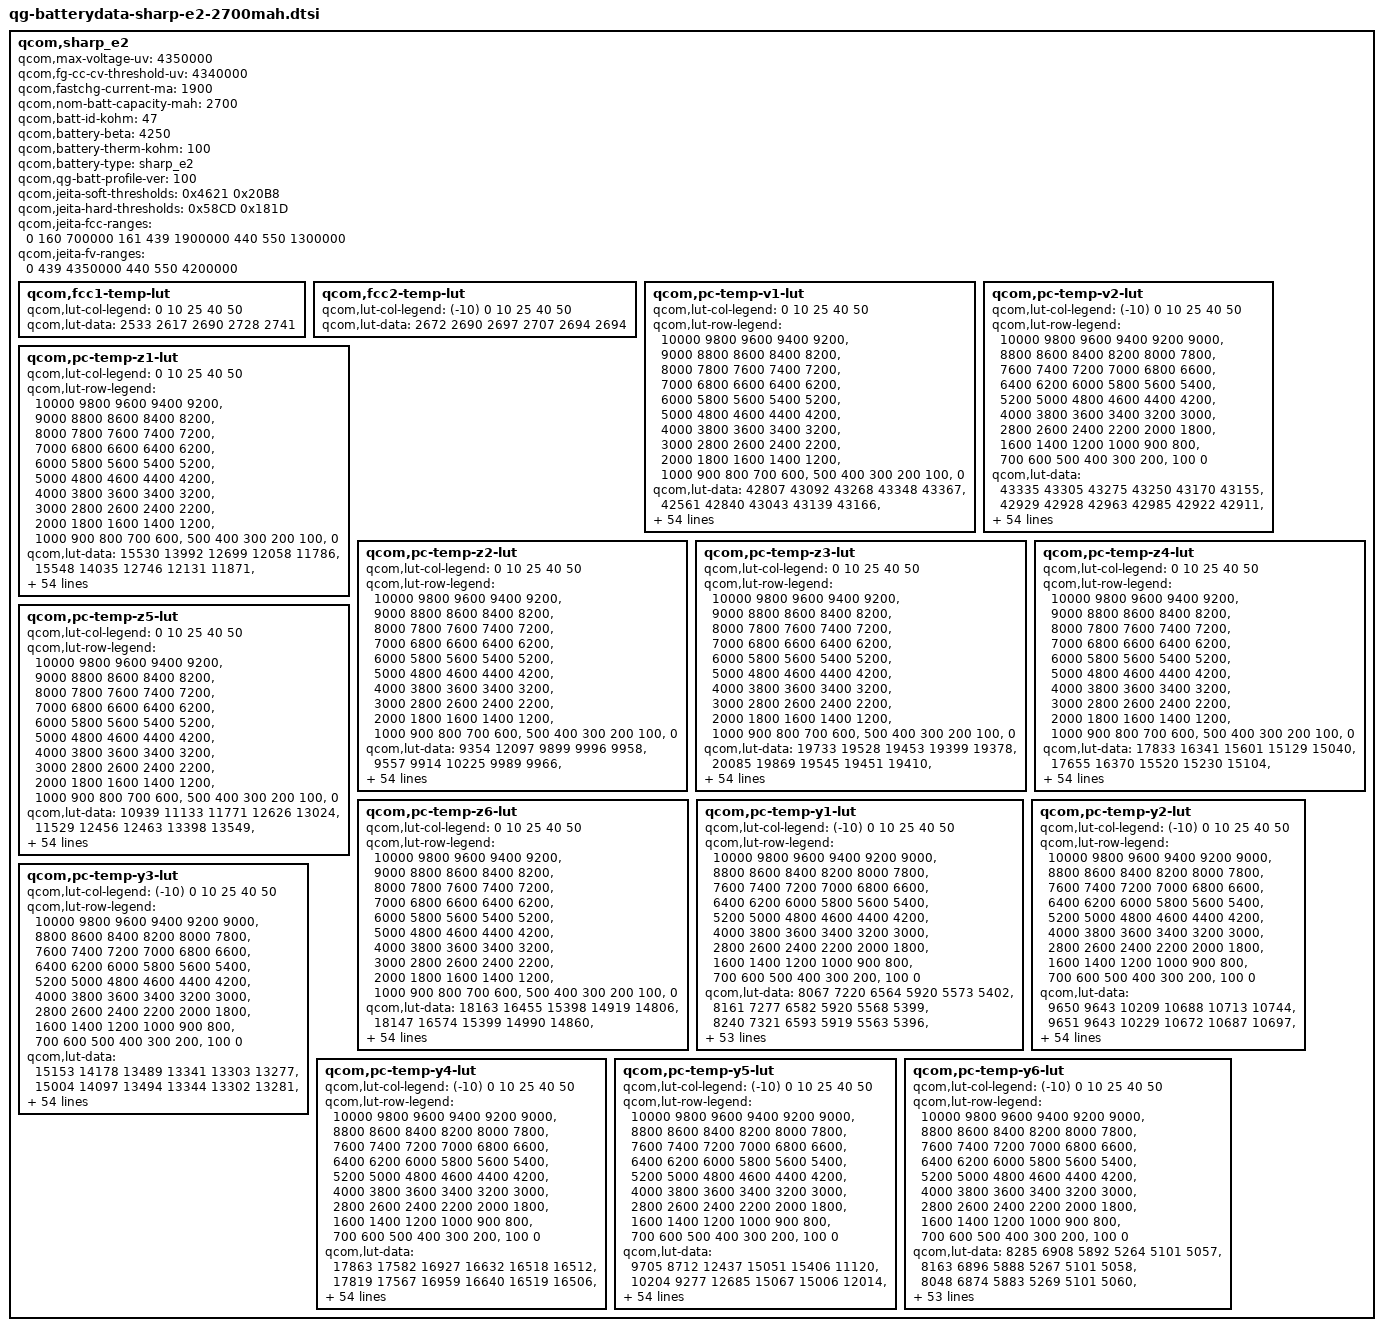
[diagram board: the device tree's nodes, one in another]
/* Copyright (c) 2018, The Linux Foundation. All rights reserved.
 *
 * This program is free software; you can redistribute it and/or modify
 * it under the terms of the GNU General Public License version 2 and
 * only version 2 as published by the Free Software Foundation.
 *
 * This program is distributed in the hope that it will be useful,
 * but WITHOUT ANY WARRANTY; without even the implied warranty of
 * MERCHANTABILITY or FITNESS FOR A PARTICULAR PURPOSE.  See the
 * GNU General Public License for more details.
 */

qcom,sharp_e2 {
	/* sharp_e2 */
	qcom,max-voltage-uv = <4350000>;
	qcom,fg-cc-cv-threshold-uv = <4340000>;
	qcom,fastchg-current-ma = <1900>;
	qcom,nom-batt-capacity-mah = <2700>;
	qcom,batt-id-kohm = <47>;
	qcom,battery-beta = <4250>;
	qcom,battery-therm-kohm = <100>;
	qcom,battery-type = "sharp_e2";
	qcom,qg-batt-profile-ver = <100>;

	qcom,jeita-soft-thresholds = <0x4621 0x20B8>;
	qcom,jeita-hard-thresholds = <0x58CD 0x181D>;

	qcom,jeita-fcc-ranges = <0 160 700000 161 439 1900000 440 550 1300000>;
	qcom,jeita-fv-ranges = <0 439 4350000 440 550 4200000>;

	qcom,fcc1-temp-lut {
		qcom,lut-col-legend = <0 10 25 40 50>;
		qcom,lut-data = <2533 2617 2690 2728 2741>;
	};

	qcom,fcc2-temp-lut {
		qcom,lut-col-legend = <(-10) 0 10 25 40 50>;
		qcom,lut-data = <2672 2690 2697 2707 2694 2694>;
	};

	qcom,pc-temp-v1-lut {
		qcom,lut-col-legend = <0 10 25 40 50>;
		qcom,lut-row-legend = <10000 9800 9600 9400 9200>,
			<9000 8800 8600 8400 8200>,
			<8000 7800 7600 7400 7200>,
			<7000 6800 6600 6400 6200>,
			<6000 5800 5600 5400 5200>,
			<5000 4800 4600 4400 4200>,
			<4000 3800 3600 3400 3200>,
			<3000 2800 2600 2400 2200>,
			<2000 1800 1600 1400 1200>,
			<1000 900 800 700 600>,
			<500 400 300 200 100>,
			<0>;
		qcom,lut-data = <42807 43092 43268 43348 43367>,
			<42561 42840 43043 43139 43166>,
			<42329 42609 42816 42914 42945>,
			<42112 42390 42590 42687 42720>,
			<41905 42175 42362 42464 42499>,
			<41702 41962 42138 42242 42279>,
			<41501 41753 41919 42021 42059>,
			<41305 41547 41704 41803 41840>,
			<41123 41347 41494 41588 41622>,
			<40954 41155 41286 41375 41409>,
			<40772 40981 41087 41167 41199>,
			<40546 40805 40901 40965 40995>,
			<40302 40602 40720 40769 40796>,
			<40104 40373 40531 40580 40603>,
			<39950 40173 40336 40394 40416>,
			<39814 40019 40155 40215 40235>,
			<39685 39882 39998 40046 40064>,
			<39564 39748 39851 39888 39905>,
			<39449 39620 39700 39727 39744>,
			<39338 39492 39551 39566 39578>,
			<39232 39361 39382 39395 39405>,
			<39132 39227 39146 39185 39211>,
			<39035 39087 38903 38938 38985>,
			<38946 38931 38744 38765 38806>,
			<38862 38782 38626 38667 38694>,
			<38783 38656 38541 38588 38603>,
			<38708 38544 38481 38505 38510>,
			<38640 38461 38433 38426 38418>,
			<38576 38401 38382 38349 38333>,
			<38516 38354 38331 38274 38253>,
			<38461 38315 38282 38205 38181>,
			<38408 38282 38236 38149 38120>,
			<38359 38251 38191 38099 38068>,
			<38312 38223 38146 38048 38013>,
			<38266 38197 38104 37997 37957>,
			<38220 38164 38060 37945 37900>,
			<38174 38128 38016 37895 37839>,
			<38120 38082 37967 37843 37775>,
			<38058 38012 37898 37776 37700>,
			<37983 37915 37797 37684 37608>,
			<37886 37806 37684 37576 37503>,
			<37761 37678 37562 37455 37385>,
			<37621 37536 37426 37319 37254>,
			<37467 37372 37265 37166 37102>,
			<37323 37249 37140 37041 36978>,
			<37229 37176 37061 36968 36905>,
			<37193 37140 37042 36945 36887>,
			<37164 37113 37021 36932 36871>,
			<37130 37085 37001 36910 36848>,
			<37052 37022 36936 36837 36765>,
			<36810 36762 36661 36553 36467>,
			<36368 36323 36231 36120 36033>,
			<35809 35762 35672 35559 35470>,
			<35057 35006 34916 34798 34708>,
			<33873 33833 33755 33637 33545>,
			<30000 30000 30000 30000 30000>;
	};

	qcom,pc-temp-v2-lut {
		qcom,lut-col-legend = <(-10) 0 10 25 40 50>;
		qcom,lut-row-legend = <10000 9800 9600 9400 9200 9000>,
			<8800 8600 8400 8200 8000 7800>,
			<7600 7400 7200 7000 6800 6600>,
			<6400 6200 6000 5800 5600 5400>,
			<5200 5000 4800 4600 4400 4200>,
			<4000 3800 3600 3400 3200 3000>,
			<2800 2600 2400 2200 2000 1800>,
			<1600 1400 1200 1000 900 800>,
			<700 600 500 400 300 200>,
			<100 0>;
		qcom,lut-data = <43335 43305 43275 43250 43170 43155>,
			<42929 42928 42963 42985 42922 42911>,
			<42563 42588 42674 42731 42683 42676>,
			<42244 42293 42411 42490 42451 42448>,
			<41965 42037 42171 42262 42229 42228>,
			<41710 41791 41942 42040 42010 42011>,
			<41461 41520 41718 41819 41793 41795>,
			<41235 41266 41501 41602 41579 41580>,
			<41073 41108 41285 41389 41368 41370>,
			<40970 41018 41069 41179 41160 41163>,
			<40843 40902 40866 40976 40958 40960>,
			<40526 40612 40691 40785 40762 40762>,
			<40074 40217 40523 40599 40572 40568>,
			<39777 39953 40331 40408 40386 40383>,
			<39594 39776 40110 40209 40205 40204>,
			<39432 39607 39891 40024 40030 40031>,
			<39255 39411 39688 39867 39867 39868>,
			<39081 39212 39491 39717 39709 39708>,
			<38916 39029 39293 39537 39534 39535>,
			<38757 38858 39092 39328 39341 39349>,
			<38614 38700 38907 39123 39148 39161>,
			<38496 38548 38746 38927 38953 38966>,
			<38392 38411 38600 38746 38766 38777>,
			<38306 38306 38470 38602 38622 38631>,
			<38234 38225 38351 38484 38509 38517>,
			<38169 38157 38244 38380 38409 38415>,
			<38108 38099 38147 38287 38315 38319>,
			<38050 38047 38061 38203 38228 38230>,
			<37994 37999 37996 38122 38149 38150>,
			<37939 37955 37945 38045 38077 38076>,
			<37885 37911 37899 37975 38009 38008>,
			<37832 37867 37853 37908 37945 37945>,
			<37780 37823 37809 37847 37884 37885>,
			<37725 37777 37765 37790 37817 37814>,
			<37667 37730 37723 37740 37742 37728>,
			<37608 37679 37677 37687 37663 37636>,
			<37546 37621 37624 37627 37578 37539>,
			<37484 37557 37563 37564 37489 37438>,
			<37419 37484 37493 37495 37407 37350>,
			<37351 37401 37413 37421 37335 37276>,
			<37282 37310 37323 37335 37257 37196>,
			<37209 37209 37217 37229 37156 37095>,
			<37134 37104 37100 37109 37039 36980>,
			<37052 37007 36977 36972 36903 36845>,
			<36957 36917 36865 36869 36817 36769>,
			<36840 36835 36785 36820 36784 36739>,
			<36778 36793 36750 36798 36769 36724>,
			<36699 36742 36704 36774 36749 36704>,
			<36588 36673 36636 36728 36708 36665>,
			<36435 36561 36543 36617 36578 36516>,
			<36199 36325 36305 36297 36233 36162>,
			<35833 35913 35862 35805 35750 35677>,
			<35289 35316 35256 35175 35126 35049>,
			<34478 34455 34415 34312 34294 34216>,
			<33103 33147 33094 33108 33164 33127>,
			<30084 30046 30023 30020 30017 30016>;
	};

	qcom,pc-temp-z1-lut {
		qcom,lut-col-legend = <0 10 25 40 50>;
		qcom,lut-row-legend = <10000 9800 9600 9400 9200>,
			<9000 8800 8600 8400 8200>,
			<8000 7800 7600 7400 7200>,
			<7000 6800 6600 6400 6200>,
			<6000 5800 5600 5400 5200>,
			<5000 4800 4600 4400 4200>,
			<4000 3800 3600 3400 3200>,
			<3000 2800 2600 2400 2200>,
			<2000 1800 1600 1400 1200>,
			<1000 900 800 700 600>,
			<500 400 300 200 100>,
			<0>;
		qcom,lut-data = <15530 13992 12699 12058 11786>,
			<15548 14035 12746 12131 11871>,
			<15563 14057 12776 12148 11882>,
			<15574 14072 12781 12154 11887>,
			<15588 14078 12780 12148 11885>,
			<15598 14080 12777 12136 11879>,
			<15640 14082 12766 12127 11873>,
			<15694 14089 12752 12120 11869>,
			<15698 14104 12744 12113 11865>,
			<15674 14111 12737 12109 11863>,
			<15648 14106 12734 12105 11860>,
			<15604 14096 12733 12103 11859>,
			<15525 14080 12733 12100 11857>,
			<15481 14056 12731 12099 11856>,
			<15472 14043 12726 12098 11856>,
			<15464 14044 12723 12097 11855>,
			<15454 14049 12728 12098 11855>,
			<15437 14052 12734 12099 11856>,
			<15418 14054 12736 12100 11858>,
			<15403 14058 12738 12103 11858>,
			<15388 14085 12740 12105 11859>,
			<15372 14125 12750 12107 11860>,
			<15352 14136 12761 12109 11862>,
			<15336 14116 12762 12111 11865>,
			<15329 14099 12759 12114 11868>,
			<15327 14109 12757 12117 11873>,
			<15322 14131 12760 12121 11877>,
			<15294 14142 12765 12127 11883>,
			<15255 14142 12772 12133 11889>,
			<15238 14141 12781 12140 11894>,
			<15234 14141 12786 12146 11900>,
			<15232 14139 12788 12151 11905>,
			<15230 14141 12789 12155 11911>,
			<15233 14155 12794 12160 11916>,
			<15238 14172 12809 12166 11921>,
			<15252 14179 12818 12172 11926>,
			<15276 14183 12819 12177 11931>,
			<15292 14187 12820 12182 11936>,
			<15344 14190 12822 12188 11941>,
			<15391 14193 12831 12194 11946>,
			<15396 14199 12840 12200 11951>,
			<15400 14214 12847 12205 11956>,
			<15384 14219 12855 12211 11962>,
			<15335 14201 12865 12220 11967>,
			<15336 14178 12867 12230 11974>,
			<15316 14149 12888 12237 11980>,
			<15275 14151 12872 12236 11981>,
			<15285 14152 12868 12242 11984>,
			<15299 14167 12869 12243 11988>,
			<15300 14168 12873 12250 11995>,
			<15286 14170 12893 12268 12008>,
			<15343 14194 12914 12273 12016>,
			<15373 14252 12926 12290 12031>,
			<15374 14248 12972 12319 12051>,
			<15374 14248 12972 12319 12051>,
			<15374 14248 12972 12319 12051>;
	};

	qcom,pc-temp-z2-lut {
		qcom,lut-col-legend = <0 10 25 40 50>;
		qcom,lut-row-legend = <10000 9800 9600 9400 9200>,
			<9000 8800 8600 8400 8200>,
			<8000 7800 7600 7400 7200>,
			<7000 6800 6600 6400 6200>,
			<6000 5800 5600 5400 5200>,
			<5000 4800 4600 4400 4200>,
			<4000 3800 3600 3400 3200>,
			<3000 2800 2600 2400 2200>,
			<2000 1800 1600 1400 1200>,
			<1000 900 800 700 600>,
			<500 400 300 200 100>,
			<0>;
		qcom,lut-data = <9354 12097 9899 9996 9958>,
			<9557 9914 10225 9989 9966>,
			<9682 9800 10389 10024 10015>,
			<9702 9779 10350 10042 10046>,
			<9711 9769 10085 10023 10029>,
			<9714 9760 9909 9988 9979>,
			<9715 9754 9879 9972 9957>,
			<9717 9754 9862 9963 9954>,
			<9713 9757 9861 9957 9951>,
			<9698 9759 9865 9956 9933>,
			<9681 9760 9871 9957 9896>,
			<9666 9761 9939 9956 9878>,
			<9651 9755 10042 9955 9860>,
			<9641 9735 10089 9954 9851>,
			<9633 9725 10117 9955 9854>,
			<9627 9731 10129 9956 9858>,
			<9620 9742 10063 9958 9864>,
			<9612 9752 9964 9957 9878>,
			<9607 9762 9951 9959 9891>,
			<9605 9770 9962 9990 9909>,
			<9604 9775 9967 10030 9930>,
			<9603 9779 9963 10033 9929>,
			<9603 9785 9955 10013 9914>,
			<9603 9797 9953 9994 9905>,
			<9604 9810 9951 9955 9917>,
			<9606 9818 9952 9920 9940>,
			<9607 9825 9954 9946 9969>,
			<9583 9830 9955 10031 10012>,
			<9526 9836 9964 10071 10034>,
			<9486 9841 9991 10069 10009>,
			<9430 9846 10009 10058 9966>,
			<9377 9850 10011 10031 9924>,
			<9359 9855 10010 9990 9860>,
			<9348 9861 10009 9978 9838>,
			<9340 9868 10007 10002 9869>,
			<9337 9876 10005 10034 9913>,
			<9336 9885 10010 10058 9947>,
			<9326 9895 10019 10080 9981>,
			<9269 9904 10030 10098 10005>,
			<9205 9914 10049 10115 10026>,
			<9187 9922 10059 10125 10038>,
			<9195 9927 10058 10124 10025>,
			<9216 9936 10057 10122 10005>,
			<9255 9965 10063 10130 10007>,
			<9304 9963 10113 10126 10012>,
			<9305 9820 10169 10075 10010>,
			<9334 9821 10153 10085 10029>,
			<9344 9835 10146 10077 10031>,
			<9336 9961 10200 10093 10050>,
			<9333 10075 10211 10172 10139>,
			<9321 9889 10251 10193 10025>,
			<9285 9781 10197 10141 9958>,
			<9211 9627 10155 10123 9928>,
			<9170 9509 10124 10057 9903>,
			<9170 9509 10124 10057 9903>,
			<9170 9509 10124 10057 9903>;
	};

	qcom,pc-temp-z3-lut {
		qcom,lut-col-legend = <0 10 25 40 50>;
		qcom,lut-row-legend = <10000 9800 9600 9400 9200>,
			<9000 8800 8600 8400 8200>,
			<8000 7800 7600 7400 7200>,
			<7000 6800 6600 6400 6200>,
			<6000 5800 5600 5400 5200>,
			<5000 4800 4600 4400 4200>,
			<4000 3800 3600 3400 3200>,
			<3000 2800 2600 2400 2200>,
			<2000 1800 1600 1400 1200>,
			<1000 900 800 700 600>,
			<500 400 300 200 100>,
			<0>;
		qcom,lut-data = <19733 19528 19453 19399 19378>,
			<20085 19869 19545 19451 19410>,
			<20272 19948 19611 19496 19450>,
			<20246 19989 19645 19522 19475>,
			<20175 19996 19675 19534 19482>,
			<20148 19994 19690 19543 19486>,
			<20157 19991 19692 19543 19486>,
			<20168 19985 19693 19532 19480>,
			<20175 19975 19689 19520 19472>,
			<20182 19960 19669 19511 19463>,
			<20191 19919 19654 19501 19452>,
			<20207 19878 19648 19490 19445>,
			<20228 19889 19645 19478 19437>,
			<20234 19937 19642 19470 19429>,
			<20212 19960 19635 19466 19426>,
			<20177 19930 19626 19463 19423>,
			<20146 19880 19605 19458 19418>,
			<20117 19849 19584 19452 19408>,
			<20085 19824 19581 19450 19402>,
			<20048 19811 19582 19455 19407>,
			<20007 19820 19585 19462 19416>,
			<19965 19843 19597 19465 19417>,
			<19922 19864 19611 19466 19409>,
			<19878 19888 19611 19462 19401>,
			<19835 19904 19602 19444 19389>,
			<19794 19905 19592 19426 19379>,
			<19754 19904 19580 19427 19386>,
			<19714 19901 19570 19436 19419>,
			<19674 19894 19569 19448 19442>,
			<19636 19882 19573 19479 19456>,
			<19600 19871 19579 19505 19467>,
			<19566 19857 19587 19502 19462>,
			<19536 19843 19595 19490 19442>,
			<19508 19828 19596 19480 19428>,
			<19485 19812 19594 19472 19420>,
			<19471 19795 19590 19466 19414>,
			<19462 19776 19584 19460 19413>,
			<19453 19763 19577 19455 19412>,
			<19415 19760 19570 19450 19411>,
			<19368 19758 19564 19443 19409>,
			<19341 19753 19559 19438 19407>,
			<19313 19738 19555 19439 19404>,
			<19294 19720 19551 19440 19401>,
			<19282 19701 19545 19435 19400>,
			<19277 19506 19514 19422 19394>,
			<19277 19265 19495 19403 19382>,
			<19275 19265 19469 19404 19371>,
			<19274 19265 19464 19390 19367>,
			<19274 19264 19430 19388 19363>,
			<19274 19262 19429 19370 19354>,
			<19274 19264 19416 19367 19374>,
			<19277 19265 19396 19370 19382>,
			<19285 19268 19380 19367 19383>,
			<19292 19272 19380 19374 19386>,
			<19292 19272 19380 19374 19386>,
			<19292 19272 19380 19374 19386>;
	};

	qcom,pc-temp-z4-lut {
		qcom,lut-col-legend = <0 10 25 40 50>;
		qcom,lut-row-legend = <10000 9800 9600 9400 9200>,
			<9000 8800 8600 8400 8200>,
			<8000 7800 7600 7400 7200>,
			<7000 6800 6600 6400 6200>,
			<6000 5800 5600 5400 5200>,
			<5000 4800 4600 4400 4200>,
			<4000 3800 3600 3400 3200>,
			<3000 2800 2600 2400 2200>,
			<2000 1800 1600 1400 1200>,
			<1000 900 800 700 600>,
			<500 400 300 200 100>,
			<0>;
		qcom,lut-data = <17833 16341 15601 15129 15040>,
			<17655 16370 15520 15230 15104>,
			<17478 16231 15434 15168 15066>,
			<17302 15955 15337 15093 15010>,
			<17126 15758 15229 15033 14965>,
			<16939 15617 15137 14974 14922>,
			<16726 15502 15063 14926 14886>,
			<16520 15410 14999 14882 14854>,
			<16339 15333 14948 14854 14831>,
			<16168 15274 14906 14839 14819>,
			<16046 15234 14873 14828 14811>,
			<15983 15196 14836 14817 14803>,
			<15937 15138 14803 14807 14793>,
			<15880 15060 14792 14796 14781>,
			<15803 15009 14786 14783 14768>,
			<15731 14989 14781 14769 14755>,
			<15687 14974 14780 14758 14746>,
			<15653 14961 14783 14747 14738>,
			<15637 14951 14782 14743 14735>,
			<15636 14938 14780 14748 14740>,
			<15638 14913 14781 14759 14754>,
			<15642 14881 14868 14812 14794>,
			<15654 14874 14993 14945 14912>,
			<15670 14891 15033 15003 14977>,
			<15683 14913 15050 15000 14973>,
			<15695 14937 15056 14992 14964>,
			<15706 14968 15038 14975 14941>,
			<15718 14979 15003 14939 14882>,
			<15730 14969 14971 14898 14832>,
			<15737 14953 14938 14845 14794>,
			<15750 14936 14905 14799 14764>,
			<15764 14918 14872 14778 14752>,
			<15772 14901 14843 14765 14745>,
			<15775 14885 14824 14762 14743>,
			<15770 14872 14810 14764 14747>,
			<15747 14863 14803 14766 14752>,
			<15715 14855 14800 14769 14757>,
			<15702 14849 14799 14773 14763>,
			<15687 14842 14802 14780 14769>,
			<15667 14834 14816 14792 14778>,
			<15647 14832 14825 14801 14783>,
			<15620 14835 14815 14794 14780>,
			<15581 14836 14801 14783 14775>,
			<15513 14826 14797 14786 14777>,
			<15300 14928 14771 14772 14768>,
			<15275 15120 14732 14740 14734>,
			<15268 15111 14735 14719 14721>,
			<15256 15101 14725 14703 14694>,
			<15247 15089 14743 14682 14670>,
			<15236 15079 14740 14708 14688>,
			<15240 15098 14791 14758 14721>,
			<15289 15125 14826 14763 14720>,
			<15322 15141 14851 14770 14723>,
			<15364 15164 14860 14767 14723>,
			<15364 15164 14860 14767 14723>,
			<15364 15164 14860 14767 14723>;
	};

	qcom,pc-temp-z5-lut {
		qcom,lut-col-legend = <0 10 25 40 50>;
		qcom,lut-row-legend = <10000 9800 9600 9400 9200>,
			<9000 8800 8600 8400 8200>,
			<8000 7800 7600 7400 7200>,
			<7000 6800 6600 6400 6200>,
			<6000 5800 5600 5400 5200>,
			<5000 4800 4600 4400 4200>,
			<4000 3800 3600 3400 3200>,
			<3000 2800 2600 2400 2200>,
			<2000 1800 1600 1400 1200>,
			<1000 900 800 700 600>,
			<500 400 300 200 100>,
			<0>;
		qcom,lut-data = <10939 11133 11771 12626 13024>,
			<11529 12456 12463 13398 13549>,
			<11908 12849 13114 14150 14459>,
			<11995 13074 13652 14714 15162>,
			<12055 13247 14364 15184 15471>,
			<12155 13385 15053 15619 15657>,
			<12392 13516 15642 15993 15907>,
			<12692 13730 16211 16471 16340>,
			<12924 14028 16790 16727 16732>,
			<13117 14142 17387 16785 16827>,
			<13315 13898 17761 16839 16704>,
			<13584 13616 18536 16832 16628>,
			<13859 14117 19513 16793 16620>,
			<13960 15973 20000 16807 16776>,
			<13933 17002 20691 17243 17395>,
			<13861 16598 21000 17968 18214>,
			<13771 15961 20790 18559 18409>,
			<13637 15768 20491 19135 18312>,
			<13479 15752 20833 20008 18257>,
			<13279 15797 22801 22412 20083>,
			<13048 16815 25366 25018 22914>,
			<12844 19475 29759 25498 23014>,
			<12657 22841 33920 24604 20639>,
			<12479 28645 33563 23226 18174>,
			<12320 33306 29455 19749 15964>,
			<12175 34080 25531 16378 14216>,
			<12043 34168 22649 15683 14217>,
			<11918 33819 20457 15399 15208>,
			<11796 32564 19905 15531 16328>,
			<11677 30838 19819 18175 18854>,
			<11555 29336 19978 21363 21297>,
			<11441 27860 21173 22666 21477>,
			<11349 26452 23194 23543 21368>,
			<11267 25067 25134 24537 21362>,
			<11194 23771 27357 25963 22214>,
			<11134 22741 28428 26902 23081>,
			<11075 21707 28360 26557 23080>,
			<10992 21145 28179 25421 22881>,
			<10806 21669 27658 23936 22476>,
			<10638 22742 25985 21301 20776>,
			<10612 22973 24555 19510 18984>,
			<10615 21451 23876 19538 18217>,
			<10632 20490 23384 19621 17691>,
			<10682 20382 22794 18602 17210>,
			<10927 15884 22124 18227 16907>,
			<10906 10966 22565 17558 16877>,
			<10882 10954 18424 18306 16165>,
			<10870 10942 17957 17254 16934>,
			<10872 10916 15987 18546 18825>,
			<10894 10918 15929 15684 16069>,
			<10912 10984 14148 13636 14805>,
			<10884 10915 13012 13337 14714>,
			<10801 10858 12408 12945 14391>,
			<10739 10788 12218 13015 14157>,
			<10739 10788 12218 13015 14157>,
			<10739 10788 12218 13015 14157>;
	};

	qcom,pc-temp-z6-lut {
		qcom,lut-col-legend = <0 10 25 40 50>;
		qcom,lut-row-legend = <10000 9800 9600 9400 9200>,
			<9000 8800 8600 8400 8200>,
			<8000 7800 7600 7400 7200>,
			<7000 6800 6600 6400 6200>,
			<6000 5800 5600 5400 5200>,
			<5000 4800 4600 4400 4200>,
			<4000 3800 3600 3400 3200>,
			<3000 2800 2600 2400 2200>,
			<2000 1800 1600 1400 1200>,
			<1000 900 800 700 600>,
			<500 400 300 200 100>,
			<0>;
		qcom,lut-data = <18163 16455 15398 14919 14806>,
			<18147 16574 15399 14990 14860>,
			<18103 16509 15390 14986 14861>,
			<18006 16366 15366 14979 14861>,
			<17830 16251 15316 14962 14854>,
			<17666 16157 15270 14935 14834>,
			<17529 16076 15232 14910 14815>,
			<17407 16012 15194 14884 14797>,
			<17305 15959 15159 14863 14782>,
			<17213 15906 15126 14850 14771>,
			<17141 15850 15099 14839 14761>,
			<17096 15800 15079 14828 14752>,
			<17061 15767 15063 14816 14743>,
			<17018 15743 15052 14806 14734>,
			<16957 15719 15045 14798 14726>,
			<16894 15691 15038 14790 14719>,
			<16850 15666 15026 14782 14711>,
			<16815 15648 15016 14774 14702>,
			<16786 15630 15015 14771 14698>,
			<16758 15620 15016 14775 14702>,
			<16730 15620 15018 14784 14712>,
			<16704 15625 15064 14810 14732>,
			<16679 15635 15126 14868 14778>,
			<16654 15655 15142 14892 14803>,
			<16630 15678 15147 14884 14798>,
			<16607 15696 15148 14871 14789>,
			<16583 15713 15137 14862 14782>,
			<16555 15718 15118 14854 14775>,
			<16526 15712 15105 14847 14769>,
			<16505 15702 15095 14841 14762>,
			<16488 15692 15087 14835 14755>,
			<16474 15679 15079 14826 14746>,
			<16459 15668 15073 14815 14733>,
			<16443 15658 15068 14809 14727>,
			<16430 15650 15064 14807 14725>,
			<16424 15643 15061 14805 14724>,
			<16420 15637 15059 14805 14725>,
			<16421 15634 15058 14805 14727>,
			<16430 15635 15059 14806 14730>,
			<16436 15636 15067 14809 14734>,
			<16432 15637 15071 14812 14736>,
			<16427 15636 15069 14811 14734>,
			<16413 15634 15066 14808 14731>,
			<16374 15626 15066 14808 14733>,
			<16274 15573 15048 14799 14726>,
			<16267 15548 15027 14777 14706>,
			<16260 15547 15016 14769 14696>,
			<16255 15544 15012 14756 14682>,
			<16256 15542 15005 14747 14670>,
			<16261 15546 15007 14751 14675>,
			<16275 15568 15028 14774 14702>,
			<16309 15594 15042 14782 14709>,
			<16344 15622 15054 14787 14715>,
			<16396 15662 15072 14797 14722>,
			<16396 15662 15072 14797 14722>,
			<16396 15662 15072 14797 14722>;
	};

	qcom,pc-temp-y1-lut {
		qcom,lut-col-legend = <(-10) 0 10 25 40 50>;
		qcom,lut-row-legend = <10000 9800 9600 9400 9200 9000>,
			<8800 8600 8400 8200 8000 7800>,
			<7600 7400 7200 7000 6800 6600>,
			<6400 6200 6000 5800 5600 5400>,
			<5200 5000 4800 4600 4400 4200>,
			<4000 3800 3600 3400 3200 3000>,
			<2800 2600 2400 2200 2000 1800>,
			<1600 1400 1200 1000 900 800>,
			<700 600 500 400 300 200>,
			<100 0>;
		qcom,lut-data = <8067 7220 6564 5920 5573 5402>,
			<8161 7277 6582 5920 5568 5399>,
			<8240 7321 6593 5919 5563 5396>,
			<8300 7353 6598 5917 5558 5393>,
			<8338 7372 6599 5914 5553 5389>,
			<8352 7379 6597 5910 5548 5385>,
			<8335 7366 6590 5905 5544 5380>,
			<8301 7344 6580 5899 5540 5374>,
			<8278 7339 6578 5898 5536 5371>,
			<8273 7336 6591 5901 5532 5369>,
			<8279 7335 6600 5903 5529 5367>,
			<8307 7334 6591 5900 5525 5364>,
			<8347 7332 6578 5894 5521 5362>,
			<8365 7334 6579 5892 5519 5360>,
			<8346 7338 6592 5887 5517 5357>,
			<8332 7345 6599 5884 5516 5356>,
			<8316 7373 6591 5889 5515 5356>,
			<8271 7413 6578 5898 5514 5357>,
			<8249 7414 6575 5900 5513 5357>,
			<8242 7366 6576 5899 5513 5358>,
			<8237 7330 6577 5898 5512 5358>,
			<8234 7342 6583 5900 5513 5359>,
			<8232 7362 6593 5903 5515 5359>,
			<8230 7366 6595 5904 5516 5361>,
			<8227 7365 6594 5904 5518 5363>,
			<8223 7362 6593 5905 5520 5366>,
			<8225 7343 6596 5909 5524 5369>,
			<8237 7310 6600 5912 5529 5372>,
			<8247 7302 6600 5912 5533 5375>,
			<8263 7305 6603 5909 5538 5378>,
			<8275 7307 6606 5908 5542 5382>,
			<8266 7306 6607 5911 5546 5387>,
			<8244 7303 6608 5916 5550 5391>,
			<8234 7307 6608 5918 5554 5395>,
			<8241 7338 6600 5919 5558 5398>,
			<8255 7360 6595 5919 5561 5400>,
			<8259 7349 6594 5921 5562 5404>,
			<8237 7325 6594 5923 5563 5408>,
			<8214 7314 6593 5925 5565 5411>,
			<8219 7331 6588 5928 5573 5413>,
			<8241 7350 6586 5933 5580 5415>,
			<8256 7342 6592 5944 5581 5419>,
			<8248 7324 6600 5950 5582 5424>,
			<8225 7360 6603 5949 5586 5429>,
			<8222 7355 6604 5951 5594 5436>,
			<8215 7327 6629 5965 5602 5439>,
			<8215 7341 6605 5957 5612 5440>,
			<8215 7333 6648 5955 5609 5441>,
			<8276 7369 6615 5966 5605 5441>,
			<8358 7345 6601 5964 5604 5443>,
			<8375 7347 6625 5968 5611 5449>,
			<8394 7387 6623 5983 5622 5456>,
			<8451 7484 6658 6011 5639 5467>,
			<8572 7552 6690 6027 5663 5481>,
			<8572 7552 6690 6027 5663 5481>,
			<8572 7552 6690 6027 5663 5481>;
	};

	qcom,pc-temp-y2-lut {
		qcom,lut-col-legend = <(-10) 0 10 25 40 50>;
		qcom,lut-row-legend = <10000 9800 9600 9400 9200 9000>,
			<8800 8600 8400 8200 8000 7800>,
			<7600 7400 7200 7000 6800 6600>,
			<6400 6200 6000 5800 5600 5400>,
			<5200 5000 4800 4600 4400 4200>,
			<4000 3800 3600 3400 3200 3000>,
			<2800 2600 2400 2200 2000 1800>,
			<1600 1400 1200 1000 900 800>,
			<700 600 500 400 300 200>,
			<100 0>;
		qcom,lut-data = <9650 9643 10209 10688 10713 10744>,
			<9651 9643 10229 10672 10687 10697>,
			<9651 9643 10260 10656 10662 10650>,
			<9652 9722 10291 10641 10638 10608>,
			<9652 9806 10316 10626 10617 10577>,
			<9653 9836 10326 10612 10600 10562>,
			<9653 9788 10323 10596 10585 10566>,
			<9653 9708 10319 10582 10573 10575>,
			<9653 9739 10325 10573 10574 10569>,
			<9654 10011 10367 10567 10589 10540>,
			<9655 10198 10411 10565 10606 10521>,
			<9655 10034 10440 10569 10621 10528>,
			<9654 9757 10465 10578 10638 10544>,
			<9654 9688 10486 10591 10656 10563>,
			<9654 9682 10504 10615 10678 10594>,
			<9654 9678 10517 10642 10703 10629>,
			<9654 9674 10524 10680 10735 10664>,
			<9654 9671 10530 10714 10768 10698>,
			<9654 9669 10538 10716 10786 10728>,
			<9654 9667 10546 10706 10799 10770>,
			<9654 9665 10555 10700 10804 10795>,
			<9654 9665 10570 10708 10776 10753>,
			<9654 9665 10586 10724 10731 10680>,
			<9654 9665 10592 10738 10724 10667>,
			<9654 9664 10595 10753 10749 10688>,
			<9654 9663 10594 10766 10777 10706>,
			<9654 9662 10349 10779 10795 10716>,
			<9654 9661 9954 10789 10811 10729>,
			<9653 9660 9848 10794 10833 10747>,
			<9653 9659 9828 10799 10869 10776>,
			<9653 9657 9820 10800 10893 10801>,
			<9653 9657 9931 10797 10894 10814>,
			<9653 9656 10122 10792 10891 10823>,
			<9653 9655 10128 10789 10888 10820>,
			<9653 9654 9894 10786 10879 10789>,
			<9653 9654 9713 10781 10868 10761>,
			<9653 9653 9689 10771 10842 10765>,
			<9652 9653 9676 10756 10805 10780>,
			<9652 9653 9670 10740 10799 10776>,
			<9652 9652 9666 10720 10829 10749>,
			<9652 9652 9662 10694 10852 10730>,
			<9652 9652 9660 10659 10838 10734>,
			<9652 9652 9657 10614 10808 10740>,
			<9652 9652 9656 10550 10782 10737>,
			<9652 9652 9654 10505 10736 10683>,
			<9652 9651 9654 10511 10741 10624>,
			<9652 9651 9654 10499 10735 10603>,
			<9651 9651 9653 10500 10741 10643>,
			<9651 9651 9653 10494 10761 10678>,
			<9650 9651 9653 10484 10728 10639>,
			<9650 9651 9652 10416 10711 10576>,
			<9649 9651 9652 10347 10653 10532>,
			<9648 9650 9651 10286 10609 10484>,
			<9647 9648 9650 10233 10524 10433>,
			<9647 9648 9650 10233 10524 10433>,
			<9647 9648 9650 10233 10524 10433>;
	};

	qcom,pc-temp-y3-lut {
		qcom,lut-col-legend = <(-10) 0 10 25 40 50>;
		qcom,lut-row-legend = <10000 9800 9600 9400 9200 9000>,
			<8800 8600 8400 8200 8000 7800>,
			<7600 7400 7200 7000 6800 6600>,
			<6400 6200 6000 5800 5600 5400>,
			<5200 5000 4800 4600 4400 4200>,
			<4000 3800 3600 3400 3200 3000>,
			<2800 2600 2400 2200 2000 1800>,
			<1600 1400 1200 1000 900 800>,
			<700 600 500 400 300 200>,
			<100 0>;
		qcom,lut-data = <15153 14178 13489 13341 13303 13277>,
			<15004 14097 13494 13344 13302 13281>,
			<14857 14019 13498 13346 13301 13285>,
			<14715 13947 13502 13349 13301 13289>,
			<14576 13880 13506 13351 13301 13292>,
			<14441 13821 13509 13353 13301 13294>,
			<14283 13769 13511 13355 13301 13295>,
			<14141 13723 13513 13357 13302 13296>,
			<14114 13683 13511 13358 13302 13297>,
			<14133 13643 13497 13359 13303 13298>,
			<14147 13620 13487 13360 13304 13298>,
			<14090 13617 13487 13363 13307 13298>,
			<13972 13617 13488 13365 13312 13298>,
			<13915 13612 13486 13365 13313 13299>,
			<13891 13604 13477 13361 13314 13302>,
			<13876 13592 13465 13358 13314 13305>,
			<13869 13565 13454 13356 13316 13307>,
			<13864 13527 13442 13355 13319 13309>,
			<13858 13500 13431 13353 13319 13309>,
			<13848 13478 13421 13349 13316 13306>,
			<13842 13461 13413 13344 13311 13303>,
			<13845 13445 13404 13337 13306 13297>,
			<13855 13431 13397 13331 13300 13292>,
			<13868 13429 13391 13328 13298 13290>,
			<13892 13432 13387 13325 13298 13290>,
			<13923 13439 13381 13324 13297 13290>,
			<13955 13452 13338 13326 13297 13289>,
			<13992 13476 13278 13328 13297 13287>,
			<14033 13504 13266 13327 13297 13287>,
			<14078 13544 13267 13326 13298 13288>,
			<14128 13588 13268 13326 13299 13289>,
			<14184 13633 13299 13326 13300 13290>,
			<14247 13681 13350 13326 13301 13291>,
			<14308 13736 13365 13327 13301 13291>,
			<14366 13802 13367 13327 13300 13291>,
			<14426 13872 13370 13328 13299 13291>,
			<14493 13942 13377 13327 13298 13289>,
			<14567 14015 13390 13326 13295 13288>,
			<14642 14091 13408 13327 13294 13288>,
			<14714 14172 13441 13328 13295 13288>,
			<14787 14253 13484 13330 13296 13289>,
			<14869 14329 13537 13333 13296 13289>,
			<14961 14405 13605 13336 13295 13289>,
			<15064 14490 13693 13337 13295 13287>,
			<15169 14582 13803 13342 13297 13289>,
			<15204 14579 13803 13343 13299 13295>,
			<15152 14613 13854 13346 13304 13297>,
			<15217 14704 13908 13357 13312 13305>,
			<15451 14788 13988 13369 13319 13310>,
			<15775 14895 14078 13377 13319 13305>,
			<16179 14992 14141 13371 13308 13299>,
			<16795 15147 14255 13378 13315 13303>,
			<17715 15653 14498 13399 13323 13309>,
			<19184 16485 14895 13431 13334 13317>,
			<19184 16485 14895 13431 13334 13317>,
			<19184 16485 14895 13431 13334 13317>;
	};

	qcom,pc-temp-y4-lut {
		qcom,lut-col-legend = <(-10) 0 10 25 40 50>;
		qcom,lut-row-legend = <10000 9800 9600 9400 9200 9000>,
			<8800 8600 8400 8200 8000 7800>,
			<7600 7400 7200 7000 6800 6600>,
			<6400 6200 6000 5800 5600 5400>,
			<5200 5000 4800 4600 4400 4200>,
			<4000 3800 3600 3400 3200 3000>,
			<2800 2600 2400 2200 2000 1800>,
			<1600 1400 1200 1000 900 800>,
			<700 600 500 400 300 200>,
			<100 0>;
		qcom,lut-data = <17863 17582 16927 16632 16518 16512>,
			<17819 17567 16959 16640 16519 16506>,
			<17813 17574 17016 16650 16522 16502>,
			<17837 17595 17079 16658 16526 16500>,
			<17884 17620 17132 16665 16531 16500>,
			<17946 17640 17157 16671 16536 16500>,
			<18051 17679 17160 16673 16541 16502>,
			<18170 17750 17162 16676 16547 16507>,
			<18209 17831 17171 16680 16553 16513>,
			<18214 17964 17204 16688 16562 16520>,
			<18205 18041 17245 16698 16569 16528>,
			<18002 17840 17299 16716 16576 16538>,
			<17634 17496 17350 16740 16583 16549>,
			<17512 17400 17346 16758 16594 16559>,
			<17498 17389 17267 16774 16610 16569>,
			<17483 17375 17185 16794 16630 16580>,
			<17439 17333 17137 16844 16662 16603>,
			<17367 17267 17094 16895 16694 16628>,
			<17306 17204 17031 16891 16699 16634>,
			<17252 17140 16937 16828 16687 16634>,
			<17211 17079 16858 16755 16668 16634>,
			<17193 17014 16808 16674 16611 16591>,
			<17180 16957 16770 16602 16536 16522>,
			<17172 16945 16734 16585 16520 16505>,
			<17163 16945 16697 16580 16520 16505>,
			<17158 16945 16680 16578 16520 16505>,
			<17158 16947 16731 16583 16527 16511>,
			<17160 16950 16816 16591 16541 16524>,
			<17163 16951 16845 16598 16556 16538>,
			<17172 16948 16855 16606 16572 16553>,
			<17180 16947 16858 16610 16588 16568>,
			<17181 16951 16819 16609 16604 16586>,
			<17181 16962 16754 16607 16617 16602>,
			<17181 16972 16748 16606 16617 16604>,
			<17188 16980 16797 16604 16601 16586>,
			<17200 16988 16844 16602 16580 16564>,
			<17213 16995 16870 16598 16554 16539>,
			<17226 17002 16889 16594 16527 16515>,
			<17242 17003 16898 16597 16522 16511>,
			<17266 16999 16903 16610 16528 16518>,
			<17297 16993 16905 16623 16534 16522>,
			<17329 16984 16899 16638 16538 16522>,
			<17362 16977 16890 16647 16540 16520>,
			<17400 16982 16880 16649 16521 16499>,
			<17433 17005 16884 16651 16516 16492>,
			<17394 17008 16885 16642 16540 16514>,
			<17306 17013 16915 16672 16559 16540>,
			<17291 17055 16985 16718 16585 16572>,
			<17376 17110 17053 16777 16628 16616>,
			<17512 17155 17127 16811 16624 16583>,
			<17674 17135 17125 16754 16553 16517>,
			<17886 17108 17092 16742 16556 16516>,
			<18280 17262 17090 16797 16582 16533>,
			<19266 17737 17325 16907 16699 16633>,
			<19266 17737 17325 16907 16699 16633>,
			<19266 17737 17325 16907 16699 16633>;
	};

	qcom,pc-temp-y5-lut {
		qcom,lut-col-legend = <(-10) 0 10 25 40 50>;
		qcom,lut-row-legend = <10000 9800 9600 9400 9200 9000>,
			<8800 8600 8400 8200 8000 7800>,
			<7600 7400 7200 7000 6800 6600>,
			<6400 6200 6000 5800 5600 5400>,
			<5200 5000 4800 4600 4400 4200>,
			<4000 3800 3600 3400 3200 3000>,
			<2800 2600 2400 2200 2000 1800>,
			<1600 1400 1200 1000 900 800>,
			<700 600 500 400 300 200>,
			<100 0>;
		qcom,lut-data = <9705 8712 12437 15051 15406 11120>,
			<10204 9277 12685 15067 15006 12014>,
			<10606 10423 12930 15028 14516 12871>,
			<10904 11248 13170 14946 14005 13599>,
			<11091 11748 13402 14831 13545 14107>,
			<11159 11920 13623 14692 13205 14300>,
			<11050 11578 13880 14521 12944 14168>,
			<10861 11019 14099 14314 12709 13889>,
			<11134 11177 13970 14080 12530 13625>,
			<13292 12776 13085 13791 12322 13347>,
			<14937 13878 12507 13525 12220 13061>,
			<13863 13392 13375 13313 12365 12713>,
			<11779 12556 14796 13122 12584 12402>,
			<11211 12348 15223 12932 12589 12366>,
			<11289 12368 15315 12710 12382 12487>,
			<11360 12373 15416 12609 12244 12608>,
			<11389 12224 15639 12797 12310 12660>,
			<11417 11979 15898 13225 12495 12705>,
			<11407 11850 16041 13970 12931 12915>,
			<11206 11776 16140 15430 14216 13775>,
			<10965 11679 16183 16218 15111 14575>,
			<10814 11425 16078 16077 15217 14993>,
			<10691 11073 15896 15869 15273 15296>,
			<10658 10872 15846 15757 15244 15321>,
			<10677 10744 15872 15352 15020 15118>,
			<10695 10677 15821 15117 14768 14811>,
			<10696 10663 14027 15535 14517 14216>,
			<10691 10655 11259 16090 14283 13511>,
			<10683 10669 10640 16179 14263 13371>,
			<10661 10788 10599 16105 14429 13477>,
			<10640 10920 10585 16095 14669 13632>,
			<10675 10993 11050 16404 15037 13883>,
			<10775 11053 11833 16806 15482 14259>,
			<10820 11140 11995 16952 15814 14681>,
			<10799 11281 11769 17029 16328 15244>,
			<10765 11380 11593 17042 16669 15573>,
			<10746 11405 11590 16534 16309 15486>,
			<10744 11422 11593 15778 15548 15293>,
			<10753 11428 11599 15313 15157 15156>,
			<10754 11410 11640 14866 14941 14843>,
			<10756 11374 11672 14538 14739 14527>,
			<10791 11239 11657 14274 14340 14346>,
			<10914 11074 11626 14076 13940 14207>,
			<11068 11023 11573 13945 14323 14124>,
			<11185 10981 11501 14005 14337 14288>,
			<11244 11047 11505 13961 13343 13790>,
			<11400 11193 11605 13601 13403 13394>,
			<11490 11248 11496 13671 13886 13915>,
			<11352 11387 11659 13990 14230 14176>,
			<11175 11655 12296 14381 14442 13805>,
			<10827 11607 12231 14151 13992 14159>,
			<10389 11309 11631 14487 15398 14924>,
			<9960 10738 11496 14810 16304 15918>,
			<9524 10052 10861 15450 17283 17612>,
			<9524 10052 10861 15450 17283 17612>,
			<9524 10052 10861 15450 17283 17612>;
	};

	qcom,pc-temp-y6-lut {
		qcom,lut-col-legend = <(-10) 0 10 25 40 50>;
		qcom,lut-row-legend = <10000 9800 9600 9400 9200 9000>,
			<8800 8600 8400 8200 8000 7800>,
			<7600 7400 7200 7000 6800 6600>,
			<6400 6200 6000 5800 5600 5400>,
			<5200 5000 4800 4600 4400 4200>,
			<4000 3800 3600 3400 3200 3000>,
			<2800 2600 2400 2200 2000 1800>,
			<1600 1400 1200 1000 900 800>,
			<700 600 500 400 300 200>,
			<100 0>;
		qcom,lut-data = <8285 6908 5892 5264 5101 5057>,
			<8163 6896 5888 5267 5101 5058>,
			<8048 6874 5883 5269 5101 5060>,
			<7940 6844 5876 5270 5101 5061>,
			<7841 6809 5869 5271 5101 5063>,
			<7753 6770 5860 5271 5102 5064>,
			<7665 6714 5850 5271 5103 5066>,
			<7591 6660 5839 5270 5104 5067>,
			<7565 6654 5829 5269 5106 5069>,
			<7557 6680 5818 5270 5108 5072>,
			<7547 6697 5813 5271 5110 5074>,
			<7451 6615 5819 5276 5114 5077>,
			<7281 6469 5830 5283 5118 5080>,
			<7206 6419 5827 5286 5123 5083>,
			<7181 6408 5797 5287 5127 5088>,
			<7161 6395 5764 5289 5133 5093>,
			<7138 6366 5741 5300 5143 5101>,
			<7116 6329 5720 5314 5154 5109>,
			<7094 6302 5694 5312 5155 5111>,
			<7070 6279 5662 5290 5149 5109>,
			<7055 6263 5636 5265 5139 5105>,
			<7055 6252 5618 5237 5119 5088>,
			<7060 6243 5604 5212 5093 5065>,
			<7067 6243 5596 5207 5088 5059>,
			<7083 6254 5590 5205 5087 5059>,
			<7104 6271 5587 5205 5088 5059>,
			<7128 6293 5589 5208 5090 5060>,
			<7157 6323 5593 5213 5094 5063>,
			<7189 6357 5601 5218 5099 5067>,
			<7226 6398 5621 5221 5105 5072>,
			<7267 6444 5645 5224 5111 5078>,
			<7309 6492 5667 5227 5117 5084>,
			<7353 6543 5693 5229 5122 5090>,
			<7399 6598 5726 5231 5122 5091>,
			<7445 6657 5769 5235 5118 5086>,
			<7493 6718 5816 5237 5112 5080>,
			<7546 6780 5866 5240 5104 5072>,
			<7603 6844 5921 5242 5095 5065>,
			<7663 6907 5982 5248 5094 5064>,
			<7727 6971 6051 5259 5097 5067>,
			<7793 7033 6124 5272 5101 5069>,
			<7864 7091 6201 5288 5103 5069>,
			<7941 7150 6284 5305 5104 5070>,
			<8029 7220 6378 5321 5100 5063>,
			<8122 7297 6486 5342 5101 5062>,
			<8151 7300 6487 5335 5111 5074>,
			<8097 7328 6538 5353 5120 5084>,
			<8147 7409 6607 5383 5134 5098>,
			<8384 7490 6691 5421 5152 5115>,
			<8732 7583 6781 5445 5151 5101>,
			<9139 7656 6837 5436 5124 5080>,
			<9751 7781 6926 5467 5132 5083>,
			<10682 8294 7127 5544 5150 5094>,
			<12140 9151 7580 5648 5196 5132>,
			<12140 9151 7580 5648 5196 5132>,
			<12140 9151 7580 5648 5196 5132>;
	};

};
